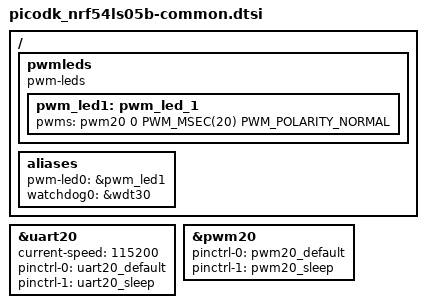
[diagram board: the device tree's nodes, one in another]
/*
 * Copyright (c) 2025 Nordic Semiconductor ASA
 *
 * SPDX-License-Identifier: LicenseRef-Nordic-5-Clause
 */

#include "picodk_nrf54ls05b-pinctrl.dtsi"

/ {
	pwmleds {
		compatible = "pwm-leds";

		pwm_led1: pwm_led_1 {
			pwms = <&pwm20 0 PWM_MSEC(20) PWM_POLARITY_NORMAL>;
		};
	};

	aliases {
		pwm-led0 = &pwm_led1;
		watchdog0 = &wdt30;
	};
};

&uart20 {
	current-speed = <115200>;
	pinctrl-0 = <&uart20_default>;
	pinctrl-1 = <&uart20_sleep>;
	pinctrl-names = "default", "sleep";
};

&pwm20 {
	status = "okay";
	pinctrl-0 = <&pwm20_default>;
	pinctrl-1 = <&pwm20_sleep>;
	pinctrl-names = "default", "sleep";
};
